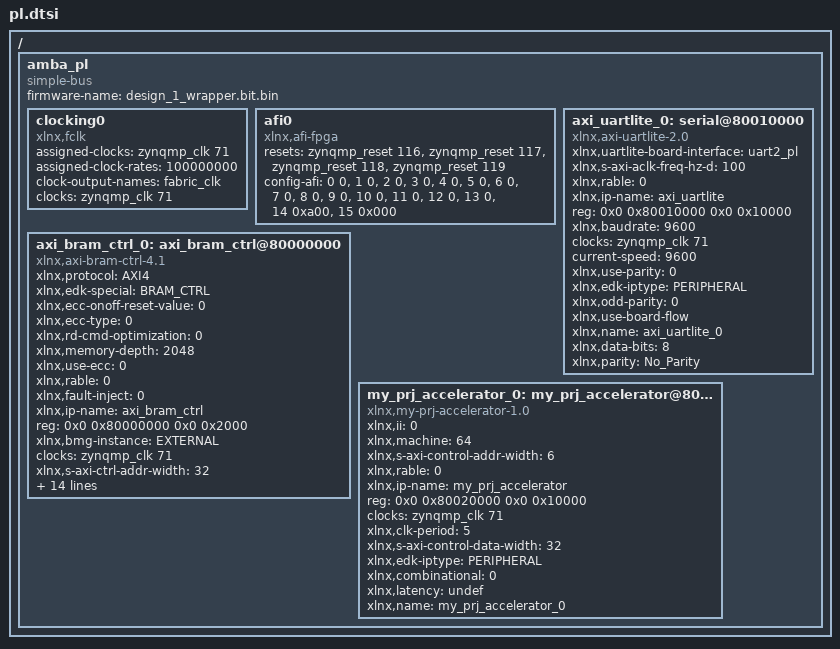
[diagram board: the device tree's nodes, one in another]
/ {
	amba_pl: amba_pl {
		ranges;
		compatible = "simple-bus";
		#address-cells = <2>;
		#size-cells = <2>;
		firmware-name = "design_1_wrapper.bit.bin";
		clocking0: clocking0 {
			compatible = "xlnx,fclk";
			status = "okay";
			assigned-clocks = <&zynqmp_clk 71>;
			assigned-clock-rates = <100000000>;
			#clock-cells = <0>;
			clock-output-names = "fabric_clk";
			clocks = <&zynqmp_clk 71>;
		};
		afi0: afi0 {
			status = "okay";
			compatible = "xlnx,afi-fpga";
			resets = <&zynqmp_reset 116>, <&zynqmp_reset 117>, <&zynqmp_reset 118>, <&zynqmp_reset 119>;
			config-afi = < 0 0>, <1 0>, <2 0>, <3 0>, <4 0>, <5 0>, <6 0>, <7 0>, <8 0>, <9 0>, <10 0>, <11 0>, <12 0>, <13 0>, <14 0xa00>, <15 0x000>;
		};
		axi_bram_ctrl_0: axi_bram_ctrl@80000000 {
			xlnx,protocol = "AXI4";
			xlnx,edk-special = "BRAM_CTRL";
			compatible = "xlnx,axi-bram-ctrl-4.1";
			xlnx,ecc-onoff-reset-value = <0>;
			xlnx,ecc-type = <0>;
			xlnx,rd-cmd-optimization = <0>;
			xlnx,memory-depth = <2048>;
			xlnx,use-ecc = <0>;
			xlnx,rable = <0>;
			xlnx,fault-inject = <0>;
			xlnx,ip-name = "axi_bram_ctrl";
			reg = <0x0 0x80000000 0x0 0x2000>;
			xlnx,bmg-instance = "EXTERNAL";
			clocks = <&zynqmp_clk 71>;
			xlnx,s-axi-ctrl-addr-width = <32>;
			xlnx,read-latency = <1>;
			xlnx,id-width = <0>;
			xlnx,s-axi-supports-narrow-burst = <0>;
			xlnx,supports-narrow-burst = <0>;
			xlnx,single-port-bram = <0>;
			xlnx,ecc = <0>;
			xlnx,edk-iptype = "PERIPHERAL";
			status = "okay";
			clock-names = "s_axi_aclk";
			xlnx,data-width = <32>;
			xlnx,bram-addr-width = <11>;
			xlnx,bram-inst-mode = "EXTERNAL";
			xlnx,s-axi-ctrl-data-width = <32>;
			xlnx,mem-depth = <2048>;
			xlnx,s-axi-id-width = <1>;
			xlnx,name = "axi_bram_ctrl_0";
		};
		axi_uartlite_0: serial@80010000 {
			compatible = "xlnx,axi-uartlite-2.0" , "xlnx,xps-uartlite-1.00.a";
			xlnx,uartlite-board-interface = "uart2_pl";
			xlnx,s-axi-aclk-freq-hz-d = <100>;
			xlnx,rable = <0>;
			xlnx,ip-name = "axi_uartlite";
			reg = <0x0 0x80010000 0x0 0x10000>;
			xlnx,baudrate = <9600>;
			clocks = <&zynqmp_clk 71>;
			current-speed = <9600>;
			xlnx,use-parity = <0>;
			xlnx,edk-iptype = "PERIPHERAL";
			xlnx,odd-parity = <0>;
			status = "okay";
			clock-names = "s_axi_aclk";
			xlnx,use-board-flow;
			xlnx,name = "axi_uartlite_0";
			xlnx,data-bits = <8>;
			xlnx,parity = "No_Parity";
		};
		my_prj_accelerator_0: my_prj_accelerator@80020000 {
			compatible = "xlnx,my-prj-accelerator-1.0";
			xlnx,ii = <0>;
			xlnx,machine = <64>;
			xlnx,s-axi-control-addr-width = <6>;
			xlnx,rable = <0>;
			xlnx,ip-name = "my_prj_accelerator";
			reg = <0x0 0x80020000 0x0 0x10000>;
			clocks = <&zynqmp_clk 71>;
			xlnx,clk-period = <5>;
			xlnx,s-axi-control-data-width = <32>;
			xlnx,edk-iptype = "PERIPHERAL";
			status = "okay";
			clock-names = "ap_clk";
			xlnx,combinational = <0>;
			xlnx,latency = "undef";
			xlnx,name = "my_prj_accelerator_0";
		};
	};
};
